AUTOSAR XML (schema 4-3-0)
package /test
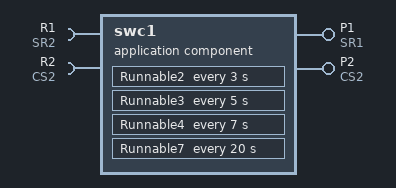
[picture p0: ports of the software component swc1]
  application sw component type swc1
    provide port P1: provided-com-specs=[SR1_DE1, SR1_DE2, SR1_DE3], provided-interface=SR1
    provide port P2: provided-com-specs=[OP1, OP2], provided-interface=CS2
    require port R1: required-com-specs=[SR2_DE1, SR2_DE2, SR2_DE3], required-interface=SR2
    require port R2: required-com-specs=[OP1, OP2], required-interface=CS2
    behavior swc1_InternalBehavior
      events:
        init event Event1: start-on-event=Runnable1
        timing event Event2: start-on-event=Runnable2, period=3
        timing event Event3: start-on-event=Runnable3, period=5
        timing event Event4: start-on-event=Runnable4, period=7
        data received event Event5: start-on-event=Runnable5, data=R1.SR2_DE1
        operation invoked event Event6: start-on-event=Runnable6, operation=P2.OP1
        timing event Event7: start-on-event=Runnable7, period=20
        data received event Event8: start-on-event=Runnable8, data=R1.SR2_DE1
      8 x runnable:
        Runnable{1..8}
  swc implementation swc1_Implementation: behavior=swc1_InternalBehavior
